# WKUP_WKUP_SEC_MMR0_CFG2 register map
Vendor: Texas Instruments
Peripheral module from a debugger description file (folder am62P).
Registers are 32-bit, read-write, reset 0xAA00 unless marked. A register's access mark holds for its fields unless they carry their own. Offsets are as the file gives them; lines under a group give offsets from that group; [hi:lo] are bit positions; {n}, {i} and the like mark numbered series; 'fields as' and 'values as' point back to an identical list; <NAME> marks a mode.

## WKUP_WKUP_SEC_MMR0_CFG2
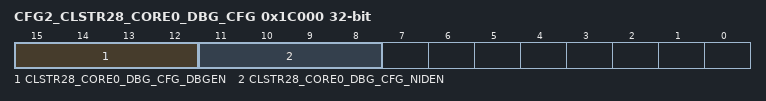
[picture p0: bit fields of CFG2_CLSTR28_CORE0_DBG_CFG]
0x1C000 CFG2_CLSTR28_CORE0_DBG_CFG
  [15:12] CLSTR28_CORE0_DBG_CFG_DBGEN — Core0 Invasive debug activate. This is a fault tolerant bitfield that must be set 4'hA to activate 4'b1010 - Activated others - Deactivated
  [11:8] CLSTR28_CORE0_DBG_CFG_NIDEN — Core0 Non-invasive debug activate. This is a fault tolerant bitfield that must be set 4'hA to activate 4'b1010 - Activated others - Deactivated
0x1C040 CFG2_CLSTR28_CORE1_DBG_CFG access not given reset not defined
